VERSION ""

NS_ :

BS_:

BU_: EPAS HIM PED EON IBST SAS EPAS TOYOTASAS

VAL_TABLE_ BRAKEMODE 3 "Reserved" 2 "Position Control" 1 "Relative Control" 0 "Disengadged" ;
VAL_TABLE_ STATUS 5 "FAULT_TIMEOUT" 4 "FAULT_STARTUP" 3 "FAULT_SCE" 2 "FAULT_SEND" 1 "FAULT_BAD_CHECKSUM" 0 "NO_FAULT" ;
VAL_TABLE_ STEERINGMODE 3 "Reserved" 2 "Position Control" 1 "Torque Control" 0 "Disengadged" ;
VAL_TABLE_ YESNO 1 "Yes" 0 "No" ;

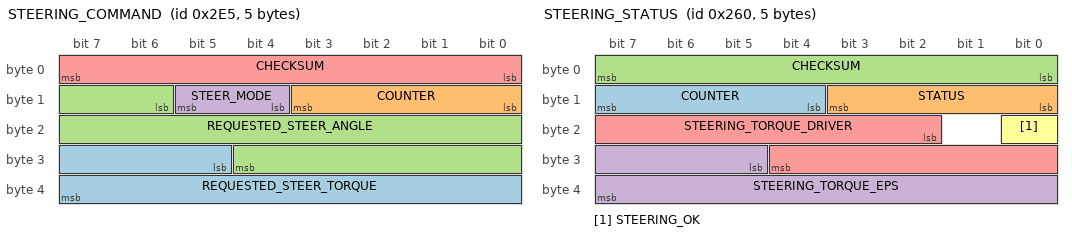
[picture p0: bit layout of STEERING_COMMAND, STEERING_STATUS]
BO_ 741 STEERING_COMMAND: 5 EON
 SG_ REQUESTED_STEER_TORQUE : 29|11@1- (0.5,0) [-512|511.5] "Nm" EPAS
 SG_ COUNTER : 8|4@1+ (1,0) [0|15] "" EPAS
 SG_ REQUESTED_STEER_ANGLE : 14|15@1- (0.1,0) [-1638.4|1638.3] "deg" EPAS
 SG_ STEER_MODE : 12|2@1+ (1,0) [0|3] "" EPAS
 SG_ CHECKSUM : 0|8@1+ (1,0) [0|255] "" EPAS

BO_ 608 STEERING_STATUS: 5 EPAS
 SG_ COUNTER : 12|4@1+ (1,0) [0|15] "" EON
 SG_ STATUS : 11|4@0+ (1,0) [0|15] "" EON
 SG_ CHECKSUM : 0|8@1+ (1,0) [0|255] "" EON
 SG_ STEERING_TORQUE_EPS : 29|11@1- (0.8,0) [-819.2|818.4] "Nm" EON
 SG_ STEERING_TORQUE_DRIVER : 18|11@1- (0.8,0) [-819.2|818.4] "Nm" EON
 SG_ STEERING_OK : 16|1@1+ (1,0) [0|1] "" EON

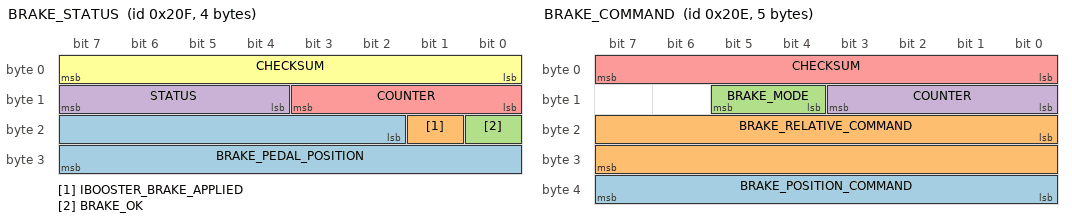
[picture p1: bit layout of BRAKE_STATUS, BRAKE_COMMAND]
BO_ 527 BRAKE_STATUS: 4 IBST
 SG_ BRAKE_PEDAL_POSITION : 18|14@1+ (0.015625,-5) [-5|47] "mm" EON
 SG_ IBOOSTER_BRAKE_APPLIED : 17|1@1+ (1,0) [0|1] "" EON
 SG_ BRAKE_OK : 16|1@1+ (1,0) [0|1] "" EON
 SG_ STATUS : 15|4@0+ (1,0) [0|15] "" EON
 SG_ COUNTER : 8|4@1+ (1,0) [0|15] "" EON
 SG_ CHECKSUM : 0|8@1+ (1,0) [0|255] "" EON

BO_ 526 BRAKE_COMMAND: 5 EON
 SG_ BRAKE_POSITION_COMMAND : 32|8@1+ (1,0) [0|255] "" IBST
 SG_ BRAKE_RELATIVE_COMMAND : 16|16@1+ (0.0078125,-252) [-252|252] "" IBST
 SG_ BRAKE_MODE : 12|2@1+ (1,0) [0|3] "" IBST
 SG_ COUNTER : 8|4@1+ (1,0) [0|15] "" IBST
 SG_ CHECKSUM : 0|8@1+ (1,0) [0|255] "" IBST

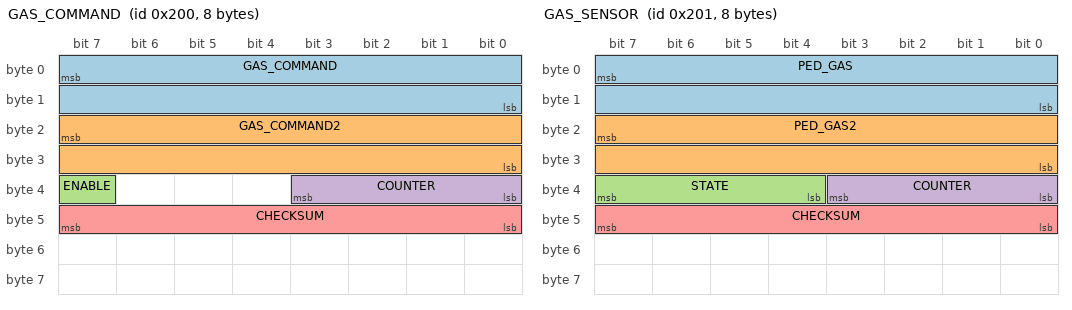
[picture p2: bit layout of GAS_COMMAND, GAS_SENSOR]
BO_ 512 GAS_COMMAND: 8 EON
 SG_ GAS_COMMAND : 7|16@0+ (0.159375,-75.555) [0|1] ""  PED
 SG_ GAS_COMMAND2 : 23|16@0+ (0.159375,-151.111) [0|1] ""  PED
 SG_ ENABLE : 39|1@0+ (1,0) [0|1] ""  PED
 SG_ COUNTER : 32|4@1+ (1,0) [0|15] ""  PED
 SG_ CHECKSUM : 40|8@1+ (1,0) [0|255] ""  PED

BO_ 513 GAS_SENSOR: 8 PED
 SG_ PED_GAS : 7|16@0+ (0.159375,-75.555) [0|1] ""  EON
 SG_ PED_GAS2 : 23|16@0+ (0.159375,-151.111) [0|1] ""  EON
 SG_ STATE : 39|4@0+ (1,0) [0|15] ""  EON
 SG_ COUNTER : 32|4@1+ (1,0) [0|15] ""  EON
 SG_ CHECKSUM : 40|8@1+ (1,0) [0|255] ""  EON

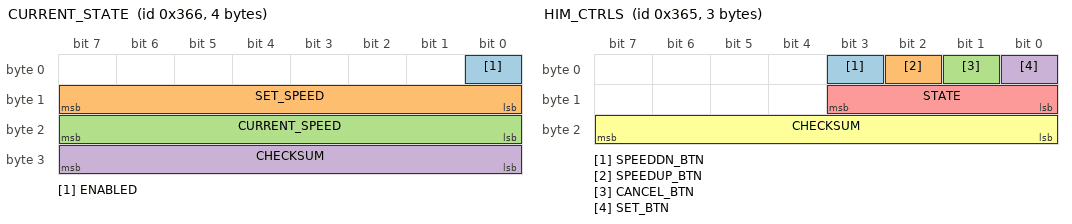
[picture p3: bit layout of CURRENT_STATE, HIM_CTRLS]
BO_ 870 CURRENT_STATE: 4 EON
 SG_ ENABLED : 0|1@0+ (1,0) [0|0] ""  HIM
 SG_ SET_SPEED : 15|8@0+ (1,0) [0|255] "mph"  HIM
 SG_ CURRENT_SPEED : 23|8@0+ (1,0) [0|255] "kph" IBST
 SG_ CHECKSUM : 24|8@1+ (1,0) [0|255] ""  HIM

BO_ 869 HIM_CTRLS: 3 HIM
 SG_ SPEEDDN_BTN : 3|1@0+ (1,0) [0|0] ""  EON
 SG_ SPEEDUP_BTN : 2|1@0+ (1,0) [0|0] ""  EON
 SG_ CANCEL_BTN : 1|1@0+ (1,0) [0|0] ""  EON
 SG_ SET_BTN : 0|1@0+ (1,0) [0|0] ""  EON
 SG_ STATE : 11|4@0+ (1,0) [0|15] ""  EON
 SG_ CHECKSUM : 16|8@1+ (1,0) [0|255] ""  EON

BO_ 1059 TOYOTA_STEERING_ANGLE_SENSOR3: 1 TOYOTASAS

BO_ 1222 TOYOTA_STEERING_ANGLE_SENSOR2: 8 TOYOTASAS

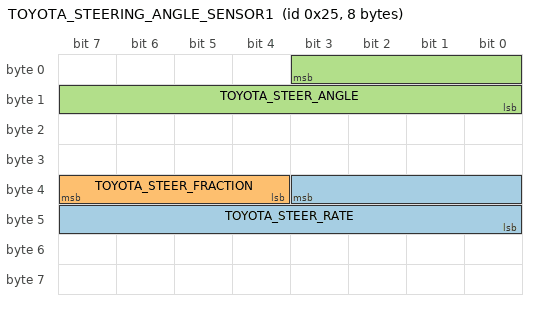
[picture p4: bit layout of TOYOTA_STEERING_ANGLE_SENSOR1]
BO_ 37 TOYOTA_STEERING_ANGLE_SENSOR1: 8 TOYOTASAS
 SG_ TOYOTA_STEER_RATE : 35|12@0- (1,0) [-2000|2000] "deg/s" EON
 SG_ TOYOTA_STEER_FRACTION : 39|4@0- (0.1,0) [-0.7|0.7] "deg" EON
 SG_ TOYOTA_STEER_ANGLE : 3|12@0- (1.5,0) [-500|500] "deg" EON

 VAL_ 527 IBOOSTER_BRAKE_APPLIED 1 "Yes" 0 "No" ;
 VAL_ 527 BRAKE_OK 1 "Yes" 0 "No" ;
 VAL_ 527 STATUS 5 "FAULT_TIMEOUT" 4 "FAULT_STARTUP" 3 "FAULT_SCE" 2 "FAULT_SEND" 1 "FAULT_BAD_CHECKSUM" 0 "NO_FAULT" ;
 VAL_ 526 BRAKE_MODE 3 "Reserved" 2 "Position Control" 1 "Relative Control" 0 "Disengadged" ;

 VAL_ 741 STEER_MODE 3 "Reserved" 2 "Position Control" 1 "Torque Control" 0 "Disengadged" ;
 VAL_ 608 STATUS 5 "FAULT_TIMEOUT" 4 "FAULT_STARTUP" 3 "FAULT_SCE" 2 "FAULT_SEND" 1 "FAULT_BAD_CHECKSUM" 0 "NO_FAULT" ;
 VAL_ 608 STEERING_OK 1 "Yes" 0 "No" ;
 VAL_ 870 ENABLED 1 "Yes" 0 "No" ;
 VAL_ 512 ENABLE 1 "Yes" 0 "No" ;
 VAL_ 869 STATE 5 "FAULT_TIMEOUT" 4 "FAULT_STARTUP" 3 "FAULT_SCE" 2 "FAULT_SEND" 1 "FAULT_BAD_CHECKSUM" 0 "NO_FAULT" ;
 VAL_ 869 SPEEDUP_BTN 1 "Yes" 0 "No" ;
 VAL_ 869 SPEEDDN_BTN 1 "Yes" 0 "No" ;
 VAL_ 869 CANCEL_BTN 1 "Yes" 0 "No" ;
 VAL_ 869 SET_BTN 1 "Yes" 0 "No" ;
 VAL_ 513 STATE 5 "FAULT_TIMEOUT" 4 "FAULT_STARTUP" 3 "FAULT_SCE" 2 "FAULT_SEND" 1 "FAULT_BAD_CHECKSUM" 0 "NO_FAULT" ;
